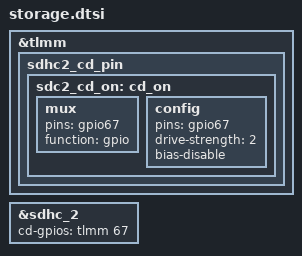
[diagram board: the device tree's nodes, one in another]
&tlmm {
	sdhc2_cd_pin {
                sdc2_cd_on: cd_on {
				mux {
                                        pins = "gpio67";
                                        function = "gpio";
                                };

                                config {
                                        pins = "gpio67";
                                        drive-strength = <2>;
                        		/delete-property/ bias-pull-up;
                        		bias-disable;
                                };
                };
        };
};

&sdhc_2 {
	cd-gpios = <&tlmm 67 0x0>;
};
